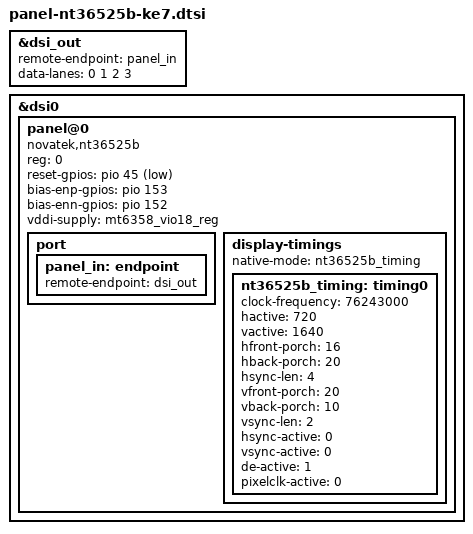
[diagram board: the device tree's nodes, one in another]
/*
 * Tecno Spark 6 (KE7) — Novatek NT36525B panel
 *
 * LCM string: nt36525b_hdp_dsi_vdo_txd_boe_ke7
 * Controller: Novatek NT36525B, 720x1640, 4-lane DSI burst video,
 *             60 Hz, BOE glass, TXD module.
 *
 * Verified wiring:
 *   reset            GPIO 45  (active low)
 *   bias ENP         GPIO 153 (active high)
 *   bias ENN         GPIO 152 (active high)
 *   DSI clock        228.5 MHz (mm_dsi0)
 *   backlight        OCP2130 i2c LED driver (led_mode 5) / disp_pwm fallback
 *
 * TIMINGS: the values below are working defaults derived from the DSI clock
 * (760 x 1672 total @ 60 Hz = 76.24 MHz). The exact porches live in the vendor
 * bootloader. Calibrate by editing display-timings only — no driver rebuild.
 */

&dsi_out {
	remote-endpoint = <&panel_in>;
	data-lanes = <0 1 2 3>;
};

&dsi0 {
	status = "okay";
	#address-cells = <1>;
	#size-cells = <0>;

	panel@0 {
		compatible = "novatek,nt36525b";
		reg = <0>;

		reset-gpios = <&pio 45 GPIO_ACTIVE_LOW>;
		bias-enp-gpios = <&pio 153 GPIO_ACTIVE_HIGH>;
		bias-enn-gpios = <&pio 152 GPIO_ACTIVE_HIGH>;
		vddi-supply = <&mt6358_vio18_reg>;

		port {
			panel_in: endpoint {
				remote-endpoint = <&dsi_out>;
			};
		};

		display-timings {
			native-mode = <&nt36525b_timing>;

			nt36525b_timing: timing0 {
				clock-frequency = <76243000>;
				hactive = <720>;
				vactive = <1640>;

				hfront-porch = <16>;
				hback-porch = <20>;
				hsync-len = <4>;

				vfront-porch = <20>;
				vback-porch = <10>;
				vsync-len = <2>;

				hsync-active = <0>;
				vsync-active = <0>;
				de-active = <1>;
				pixelclk-active = <0>;
			};
		};
	};
};
